AUTOSAR XML (schema 3.1.2)
package /Components/SWC_TrbActSys
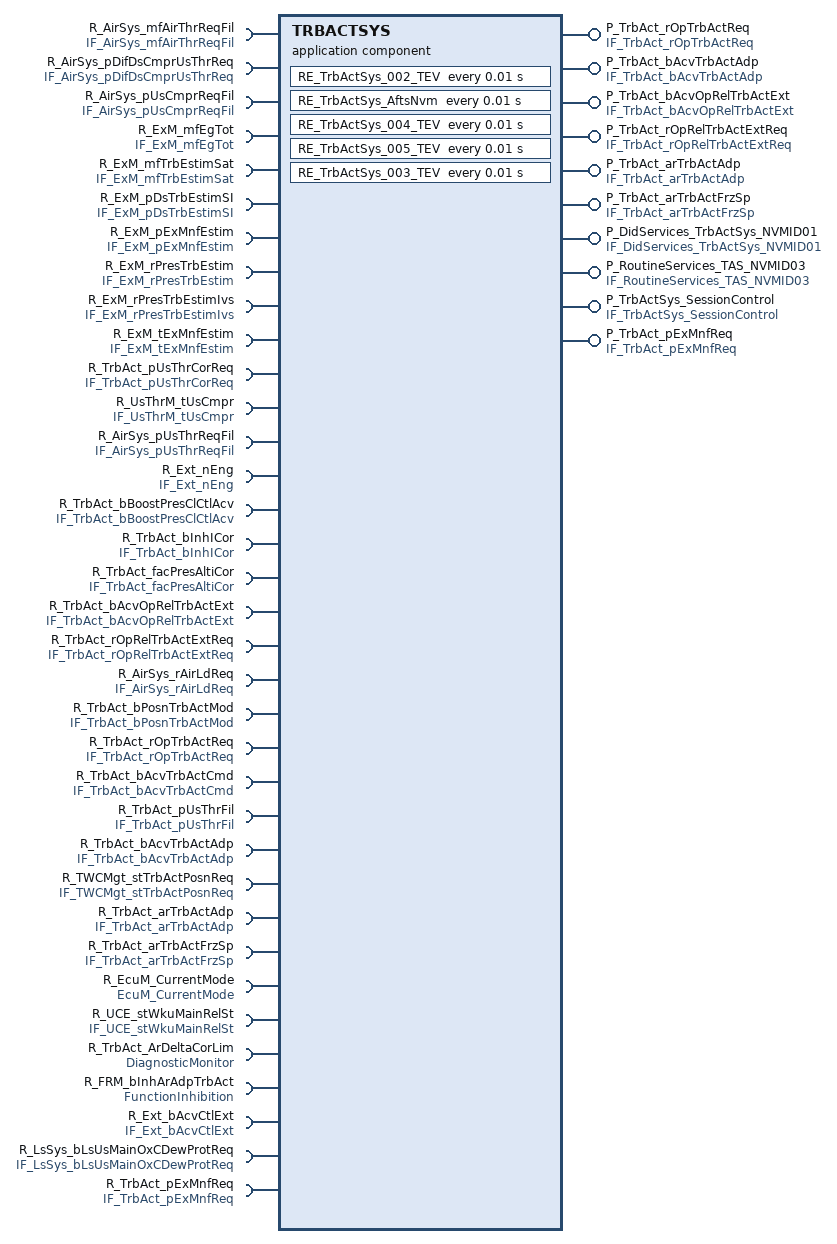
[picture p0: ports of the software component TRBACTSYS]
  application software component type TRBACTSYS
    32 x require port:
      R_AirSys_mfAirThrReqFil: unqueued-receiver-com-spec{data-element=AirSys_mfAirThrReqFil, init-value=ConstantValue, resync-time=0}, required-interface=IF_AirSys_mfAirThrReqFil  # Receiver of interface IF_AirSys_mfAirThrReqFil - Requirement Reference: [01552_10_02517-TrbActSys-I004(0)]
      R_AirSys_pDifDsCmprUsThrReq: unqueued-receiver-com-spec{data-element=AirSys_pDifDsCmprUsThrReq, init-value=ConstantValue1, resync-time=0}, required-interface=IF_AirSys_pDifDsCmprUsThrReq  # Receiver of interface IF_AirSys_pDifDsCmprUsThrReq - Requirement Reference: [01552_10_02517-TrbActSys-I005(1)]
      R_AirSys_pUsCmprReqFil: unqueued-receiver-com-spec{data-element=AirSys_pUsCmprReqFil, init-value=ConstantValue3, resync-time=0}, required-interface=IF_AirSys_pUsCmprReqFil  # Receiver of interface IF_AirSys_pUsCmprReqFil - Requirement Reference: [01552_10_02517-TrbActSys-I006(0)]
      R_ExM_mfEgTot: unqueued-receiver-com-spec{data-element=ExM_mfEgTot, init-value=ExM_mfEgTot_Cst, resync-time=0}, required-interface=IF_ExM_mfEgTot  # Receiver of interface IF_ExM_mfEgTot - Requirement Reference: [01552_10_02517-TrbActSys-I007(0)]
      R_ExM_mfTrbEstimSat: unqueued-receiver-com-spec{data-element=ExM_mfTrbEstimSat, init-value=ExM_mfTrbEstimSat_Cst, resync-time=0}, required-interface=IF_ExM_mfTrbEstimSat  # Receiver of interface IF_ExM_mfTrbEstimSat - Requirement Reference: [01552_10_02517-TrbActSys-I008(0)]
      R_ExM_pDsTrbEstimSI: unqueued-receiver-com-spec{data-element=ExM_pDsTrbEstimSI, init-value=ConstantValue5, resync-time=0}, required-interface=IF_ExM_pDsTrbEstimSI  # Receiver of interface IF_ExM_pDsTrbEstimSI - Requirement Reference: [01552_10_02517-TrbActSys-I009(0)]
      R_ExM_pExMnfEstim: unqueued-receiver-com-spec{data-element=ExM_pExMnfEstim, init-value=ConstantValue7, resync-time=0}, required-interface=IF_ExM_pExMnfEstim  # Receiver of interface IF_ExM_pExMnfEstim - Requirement Reference: [01552_10_02517-TrbActSys-I010(0)]
      R_ExM_rPresTrbEstim: unqueued-receiver-com-spec{data-element=ExM_rPresTrbEstim, init-value=ExM_rPresTrbEstim_Cst, resync-time=0}, required-interface=IF_ExM_rPresTrbEstim  # Receiver of interface IF_ExM_rPresTrbEstim - Requirement Reference: [01552_10_02517-TrbActSys-I011(0)]
      R_ExM_rPresTrbEstimIvs: unqueued-receiver-com-spec{data-element=ExM_rPresTrbEstimIvs, init-value=ExM_rPresTrbEstimIvs_Cst, resync-time=0}, required-interface=IF_ExM_rPresTrbEstimIvs  # Receiver of interface IF_ExM_rPresTrbEstimIvs - Requirement Reference: [01552_10_02517-TrbActSys-I012(1)]
      R_ExM_tExMnfEstim: unqueued-receiver-com-spec{data-element=ExM_tExMnfEstim, init-value=ExM_tExMnfEstim_Cst, resync-time=0}, required-interface=IF_ExM_tExMnfEstim  # Receiver of interface IF_ExM_tExMnfEstim - Requirement Reference: [01552_10_02517-TrbActSys-I013(0)]
      R_TrbAct_pUsThrCorReq: unqueued-receiver-com-spec{data-element=TrbAct_pUsThrCorReq, init-value=ConstantValue9, resync-time=0}, required-interface=IF_TrbAct_pUsThrCorReq  # Receiver of interface IF_TrbAct_pUsThrCorReq - Requirement Reference: [01552_10_02517-TrbActSys-I014(0)]
      R_UsThrM_tUsCmpr: unqueued-receiver-com-spec{data-element=UsThrM_tUsCmpr, init-value=ConstantValue11, resync-time=0}, required-interface=IF_UsThrM_tUsCmpr  # Receiver of interface IF_UsThrM_tUsCmpr - Requirement Reference: [01552_10_02517-TrbActSys-I016(1)]
      R_AirSys_pUsThrReqFil: unqueued-receiver-com-spec{data-element=AirSys_pUsThrReqFil, init-value=ConstantValue13, resync-time=0}, required-interface=IF_AirSys_pUsThrReqFil  # Receiver of interface IF_AirSys_pUsThrReqFil - Requirement Reference: [01552_10_02517-TrbActSys-I020(0)]
      R_Ext_nEng: unqueued-receiver-com-spec{data-element=Ext_nEng, init-value=ConstantValue15, resync-time=0}, required-interface=IF_Ext_nEng  # Receiver of interface IF_Ext_nEng - Requirement Reference: [01552_10_02517-TrbActSys-I021(0)]
      R_TrbAct_bBoostPresClCtlAcv: unqueued-receiver-com-spec{data-element=TrbAct_bBoostPresClCtlAcv, init-value=ConstantValue17, resync-time=0}, required-interface=IF_TrbAct_bBoostPresClCtlAcv  # Receiver of interface IF_TrbAct_bBoostPresClCtlAcv - Requirement Reference: [01552_10_02517-TrbActSys-I023(0)]
      R_TrbAct_bInhICor: unqueued-receiver-com-spec{data-element=TrbAct_bInhICor, init-value=ConstantValue19, resync-time=0}, required-interface=IF_TrbAct_bInhICor  # Receiver of interface IF_TrbAct_bInhICor - Requirement Reference: [01552_10_02517-TrbActSys-I024(0)]
      R_TrbAct_facPresAltiCor: unqueued-receiver-com-spec{data-element=TrbAct_facPresAltiCor, init-value=ConstantValue21, resync-time=0}, required-interface=IF_TrbAct_facPresAltiCor  # Receiver of interface IF_TrbAct_facPresAltiCor - Requirement Reference: [01552_10_02517-TrbActSys-I028(1)]
      R_TrbAct_bAcvOpRelTrbActExt: unqueued-receiver-com-spec{data-element=TrbAct_bAcvOpRelTrbActExt, init-value=TrbAct_bAcvOpRelTrbActExt_Cst, resync-time=0}, required-interface=IF_TrbAct_bAcvOpRelTrbActExt  # Receiver of interface IF_TrbAct_bAcvOpRelTrbActExt - Requirement Reference: [01552_10_02517-TrbActSys-I032(0)]
      R_TrbAct_rOpRelTrbActExtReq: unqueued-receiver-com-spec{data-element=TrbAct_rOpRelTrbActExtReq, init-value=TrbAct_rOpRelTrbActExtReq_Cst, resync-time=0}, required-interface=IF_TrbAct_rOpRelTrbActExtReq  # Receiver of interface IF_TrbAct_rOpRelTrbActExtReq - Requirement Reference: [01552_10_02517-TrbActSys-I033(0)]
      R_AirSys_rAirLdReq: unqueued-receiver-com-spec{data-element=AirSys_rAirLdReq, init-value=AirSys_rAirLdReq_Cst, resync-time=0}, required-interface=IF_AirSys_rAirLdReq  # Receiver of interface IF_AirSys_rAirLdReq - Requirement Reference: [01552_10_02517-TrbActSys-I034(0)]
      R_TrbAct_bPosnTrbActMod: unqueued-receiver-com-spec{data-element=TrbAct_bPosnTrbActMod, init-value=ConstantValue23, resync-time=0}, required-interface=IF_TrbAct_bPosnTrbActMod  # Receiver of interface IF_TrbAct_bPosnTrbActMod - Requirement Reference: [01552_10_02517-TrbActSys-I038(0)]
      R_TrbAct_rOpTrbActReq: unqueued-receiver-com-spec{data-element=TrbAct_rOpTrbActReq, init-value=ConstantValue25, resync-time=0}, required-interface=IF_TrbAct_rOpTrbActReq  # Receiver of interface IF_TrbAct_rOpTrbActReq - Requirement Reference: [01552_10_02517-TrbActSys-I050(0)]
      R_TrbAct_bAcvTrbActCmd: unqueued-receiver-com-spec{data-element=TrbAct_bAcvTrbActCmd, init-value=ConstantValue27, resync-time=0}, required-interface=IF_TrbAct_bAcvTrbActCmd  # Receiver of interface IF_TrbAct_bAcvTrbActCmd - Requirement Reference: [01552_10_02517-TrbActSys-I051(0)]
      R_TrbAct_pUsThrFil: unqueued-receiver-com-spec{data-element=TrbAct_pUsThrFil, init-value=ConstantValue29, resync-time=0}, required-interface=IF_TrbAct_pUsThrFil  # Receiver of interface IF_TrbAct_pUsThrFil - Requirement Reference: [01552_10_02517-TrbActSys-I053(0)]
      R_TrbAct_bAcvTrbActAdp: unqueued-receiver-com-spec{data-element=TrbAct_bAcvTrbActAdp, init-value=ConstantValue31, resync-time=0}, required-interface=IF_TrbAct_bAcvTrbActAdp  # Receiver of interface IF_TrbAct_bAcvTrbActAdp - Requirement Reference: [01552_10_02517-TrbActSys-I056(0)]
      R_TWCMgt_stTrbActPosnReq: unqueued-receiver-com-spec{data-element=TWCMgt_stTrbActPosnReq, init-value=TWCMgt_stTrbActPosnReq_Cst, resync-time=0}, required-interface=IF_TWCMgt_stTrbActPosnReq  # Receiver of interface IF_TWCMgt_stTrbActPosnReq - Requirement Reference: [01552_10_02517-TrbActSys-I060(0)]
      R_TrbAct_arTrbActAdp: unqueued-receiver-com-spec{data-element=TrbAct_arTrbActAdp, init-value=TrbAct_arTrbActAdp_Cst, resync-time=0}, required-interface=IF_TrbAct_arTrbActAdp  # Receiver of interface IF_TrbAct_arTrbActAdp - Requirement Reference: [01552_10_02517-TrbActSys-I066(0)]
      R_TrbAct_arTrbActFrzSp: unqueued-receiver-com-spec{data-element=TrbAct_arTrbActFrzSp, init-value=TrbAct_arTrbActFrzSp_Cst, resync-time=0}, required-interface=IF_TrbAct_arTrbActFrzSp  # Receiver of interface IF_TrbAct_arTrbActFrzSp - Requirement Reference: [01552_10_02517-TrbActSys-I067(0)]
      R_EcuM_CurrentMode: required-interface=EcuM_CurrentMode
      R_UCE_stWkuMainRelSt: required-interface=IF_UCE_stWkuMainRelSt
      R_TrbAct_ArDeltaCorLim: required-interface=DiagnosticMonitor  # 01552_10_02517-TrbActSys-I044(0)
      R_FRM_bInhArAdpTrbAct: required-interface=FunctionInhibition  # 01552_10_02517-TrbActSys-I045(0)
    9 x provide port:
      P_TrbAct_rOpTrbActReq: unqueued-sender-com-spec{data-element=TrbAct_rOpTrbActReq, can-invalidate=false, init-value=ConstantValue33}, provided-interface=IF_TrbAct_rOpTrbActReq
      P_TrbAct_bAcvTrbActAdp: unqueued-sender-com-spec{data-element=TrbAct_bAcvTrbActAdp, can-invalidate=false, init-value=ConstantValue35}, provided-interface=IF_TrbAct_bAcvTrbActAdp
      P_TrbAct_bAcvOpRelTrbActExt: unqueued-sender-com-spec{data-element=TrbAct_bAcvOpRelTrbActExt, can-invalidate=false, init-value=TrbAct_bAcvOpRelTrbActExt_Cst}, provided-interface=IF_TrbAct_bAcvOpRelTrbActExt
      P_TrbAct_rOpRelTrbActExtReq: unqueued-sender-com-spec{data-element=TrbAct_rOpRelTrbActExtReq, can-invalidate=false, init-value=TrbAct_rOpRelTrbActExtReq_Cst}, provided-interface=IF_TrbAct_rOpRelTrbActExtReq
      P_TrbAct_arTrbActAdp: unqueued-sender-com-spec{data-element=TrbAct_arTrbActAdp, can-invalidate=false, init-value=TrbAct_arTrbActAdp_Cst}, provided-interface=IF_TrbAct_arTrbActAdp
      P_TrbAct_arTrbActFrzSp: unqueued-sender-com-spec{data-element=TrbAct_arTrbActFrzSp, can-invalidate=false, init-value=TrbAct_arTrbActFrzSp_Cst}, provided-interface=IF_TrbAct_arTrbActFrzSp
      P_DidServices_TrbActSys_NVMID01: provided-interface=IF_DidServices_TrbActSys_NVMID01
        provided-com-specs:
          operation=WriteData, queue-length=1
          operation=ConditionCheckWrite, queue-length=1
          operation=ConditionCheckRead, queue-length=1
          operation=ReadDataLength, queue-length=1
          operation=ReadData, queue-length=1
      P_RoutineServices_TAS_NVMID03: provided-com-specs=[{operation=Start, queue-length=1}, {operation=RequestResults, queue-length=1}], provided-interface=IF_RoutineServices_TAS_NVMID03
      P_TrbActSys_SessionControl: provided-com-specs=[{operation=GetSesChgPermission, queue-length=1}, {operation=ChangeIndication, queue-length=1}], provided-interface=IF_TrbActSys_SessionControl
    require port R_Ext_bAcvCtlExt: unqueued-receiver-com-spec{data-element=Ext_bAcvCtlExt, init-value=Ext_bAcvCtlExt_Cst, resync-time=0}, required-interface=IF_Ext_bAcvCtlExt
    require port R_LsSys_bLsUsMainOxCDewProtReq: unqueued-receiver-com-spec{data-element=LsSys_bLsUsMainOxCDewProtReq, init-value=LsSys_bLsUsMainOxCDewProtReq_Cst, resync-time=0}, required-interface=IF_LsSys_bLsUsMainOxCDewProtReq
    provide port P_TrbAct_pExMnfReq: unqueued-sender-com-spec{data-element=TrbAct_pExMnfReq, can-invalidate=false, init-value=ConstantValue37}, provided-interface=IF_TrbAct_pExMnfReq
    require port R_TrbAct_pExMnfReq: unqueued-receiver-com-spec{data-element=TrbAct_pExMnfReq, init-value=ConstantValue39, resync-time=0}, required-interface=IF_TrbAct_pExMnfReq
  47 x constant specification:
    AirSys_rAirLdReq_Cst
      value:
        integer literal AirSys_rAirLdReq_Cst: type=DT_AirSys_rAirLdReq, value=0
    ConstantValue
      value:
        integer literal ConstantValue: type=DT_AirSys_mfAirThrReqFil, value=0
    ConstantValue1
      value:
        integer literal ConstantValue1: type=DT_AirSys_pDifDsCmprUsThrReq, value=0
    ConstantValue11
      value:
        integer literal ConstantValue11: type=DT_UsThrM_tUsCmpr, value=0
    ConstantValue13
      value:
        integer literal ConstantValue13: type=DT_AirSys_pUsThrReqFil, value=0
    ConstantValue15
      value:
        integer literal ConstantValue15: type=DT_Ext_nEng, value=0
    ConstantValue17
      value:
        boolean literal ConstantValue17: type=DT_TrbAct_bBoostPresClCtlAcv, value=false
    ConstantValue19
      value:
        boolean literal ConstantValue19: type=DT_TrbAct_bInhICor, value=false
    ConstantValue21
      value:
        integer literal ConstantValue21: type=DT_TrbAct_facPresAltiCor, value=0
    ConstantValue23
      value:
        boolean literal ConstantValue23: type=DT_TrbAct_bPosnTrbActMod, value=false
    ConstantValue25
      value:
        integer literal ConstantValue25: type=DT_TrbAct_rOpTrbActReq, value=0
    ConstantValue27
      value:
        boolean literal ConstantValue27: type=DT_TrbAct_bAcvTrbActCmd, value=false
    ConstantValue29
      value:
        integer literal ConstantValue29: type=DT_TrbAct_pUsThrFil, value=0
    ConstantValue3
      value:
        integer literal ConstantValue3: type=DT_AirSys_pUsCmprReqFil, value=0
    ConstantValue31
      value:
        boolean literal ConstantValue31: type=DT_TrbAct_bAcvTrbActAdp, value=false
    ConstantValue33
      value:
        integer literal ConstantValue33: type=DT_TrbAct_rOpTrbActReq, value=0
    ConstantValue35
      value:
        boolean literal ConstantValue35: type=DT_TrbAct_bAcvTrbActAdp, value=false
    ConstantValue37
      value:
        integer literal ConstantValue37: type=DT_TrbAct_pExMnfReq, value=0
    ConstantValue39
      value:
        integer literal ConstantValue39: type=DT_TrbAct_pExMnfReq, value=0
    ConstantValue5
      value:
        integer literal ConstantValue5: type=DT_ExM_pDsTrbEstimSI, value=0
    ConstantValue7
      value:
        integer literal ConstantValue7: type=DT_ExM_pExMnfEstim, value=0
    ConstantValue9
      value:
        integer literal ConstantValue9: type=DT_TrbAct_pUsThrCorReq, value=0
    ExM_mfEgTot_Cst
      value:
        integer literal ExM_mfEgTot_Cst: type=DT_ExM_mfEgTot, value=0
    ExM_mfTrbEstimSat_Cst
      value:
        integer literal ExM_mfTrbEstimSat_Cst: type=DT_ExM_mfTrbEstimSat, value=0
    ExM_rPresTrbEstim_Cst
      value:
        integer literal ExM_rPresTrbEstim_Cst: type=DT_ExM_rPresTrbEstim, value=0
    ExM_rPresTrbEstimIvs_Cst
      value:
        integer literal ExM_rPresTrbEstimIvs_Cst: type=DT_ExM_rPresTrbEstimIvs, value=0
    ExM_tExMnfEstim_Cst
      value:
        integer literal ExM_tExMnfEstim_Cst: type=DT_ExM_tExMnfEstim, value=4800
    Ext_bAcvCtlExt_Cst
      value:
        boolean literal Ext_bAcvCtlExt_Cst: type=DT_Ext_bAcvCtlExt, value=false
    LsSys_bLsUsMainOxCDewProtReq_Cst
      value:
        boolean literal LsSys_bLsUsMainOxCDewProtReq_Cst: type=DT_LsSys_bLsUsMainOxCDewProtReq, value=false
    TA_facAdpArTrbActErrFil_irv_Cst
      value:
        integer literal TA_facAdpArTrbActErrFil_irv_Cst: type=DT_TrbAct_facAdpArTrbActErrFil_irv, value=-65535
    TA_rOpTrbActAirExtModReq_irv_Cst
      value:
        integer literal TA_rOpTrbActAirExtModReq_irv_Cst: type=DT_TrbAct_rOpTrbActAirExtModReq_irv, value=0
    TAS_pGradUsThrMesCorFil_irv_Cst
      value:
        integer literal TAS_pGradUsThrMesCorFil_irv_Cst: type=DT_TrbAct_pGradUsThrMesCorFil_irv, value=-32768
    TrbAct_arTrbActAdp_Cst
      value:
        integer literal TrbAct_arTrbActAdp_Cst: type=DT_TrbAct_arTrbActAdp, value=0
    TrbAct_arTrbActFrzSp_Cst
      value:
        integer literal TrbAct_arTrbActFrzSp_Cst: type=DT_TrbAct_arTrbActFrzSp, value=0
    TrbAct_arTrbActReq_irv_Cst
      value:
        integer literal TrbAct_arTrbActReq_irv_Cst: type=DT_TrbAct_arTrbActReq_irv, value=0
    TrbAct_bAcvOpRelTrbActExt_Cst
      value:
        boolean literal TrbAct_bAcvOpRelTrbActExt_Cst: type=DT_TrbAct_bAcvOpRelTrbActExt, value=true
    TrbAct_effCmpr_irv_Cst
      value:
        integer literal TrbAct_effCmpr_irv_Cst: type=DT_TrbAct_effCmpr_irv, value=0
    TrbAct_effTrb_irv_Cst
      value:
        integer literal TrbAct_effTrb_irv_Cst: type=DT_TrbAct_effTrb_irv, value=0
    TrbAct_facAdpArTrbActErr_irv_Cst
      value:
        integer literal TrbAct_facAdpArTrbActErr_irv_Cst: type=DT_TrbAct_facAdpArTrbActErr_irv, value=-65535
    TrbAct_pGradUsThrReqFil_irv_Cst
      value:
        integer literal TrbAct_pGradUsThrReqFil_irv_Cst: type=DT_TrbAct_pGradUsThrReqFil_irv, value=-32768
    TrbAct_rOpRelTrbActExtReq_Cst
      value:
        integer literal TrbAct_rOpRelTrbActExtReq_Cst: type=DT_TrbAct_rOpRelTrbActExtReq, value=0
    TrbActSys_ctLockRqAftsNvm_Cst
      value:
        integer literal TrbActSys_ctLockRqAftsNvm_Cst: type=DT_TrbActSys_ctLockRqAftsNvm, value=0
    TrbActSys_IDAftsNvm_Cst
      value:
        integer literal TrbActSys_IDAftsNvm_Cst: type=DT_TrbActSys_IDAftsNvm, value=0
    TrbActSys_LockedAftsNvm_Cst
      value:
        boolean literal TrbActSys_LockedAftsNvm_Cst: type=DT_TrbActSys_LockedAftsNvm, value=false
    TrbActSys_stAftsNvm_Cst
      value:
        integer literal TrbActSys_stAftsNvm_Cst: type=DT_TrbActSys_stAftsNvm, value=0
    TrbActSys_stRstNvmRtn_Cst
      value:
        integer literal TrbActSys_stRstNvmRtn_Cst: type=DT_TrbActSys_stRstNvmRtn, value=0
    TWCMgt_stTrbActPosnReq_Cst
      value:
        integer literal TWCMgt_stTrbActPosnReq_Cst: type=DT_TWCMgt_stTrbActPosnReq, value=0
  internal behavior IB_TrbActSys: component=TRBACTSYS
    operation invoked event EV_TAS_AftsNvmWrite_NVMID01: start-on-event=RE_TrbActSys_AftsNvmWrite, operation=P_DidServices_TrbActSys_NVMID01.WriteData
    operation invoked event EV_TAS_AftsGetSesChgPerm: start-on-event=RE_TrbActSys_AftsGetSesChgPerm, operation=P_TrbActSys_SessionControl.GetSesChgPermission
    timing event EV_TrbActSys_002_TEV: start-on-event=RE_TrbActSys_002_TEV, period=0.01
    timing event EV_TrbActSys_AftsNvm: start-on-event=RE_TrbActSys_AftsNvm, period=0.01
    mode switch event EV_TrbActSys_AftrsInit: start-on-event=RE_TrbActSys_AftrsInit, activation=ENTRY, mode=R_EcuM_CurrentMode.currentMode.RUN
    mode switch event EV_TrbActSys_001_MSE: start-on-event=RE_TrbActSys_001_MSE, activation=ENTRY, mode=R_EcuM_CurrentMode.currentMode.RUN
    timing event EV_TrbActSys_004_TEV: start-on-event=RE_TrbActSys_004_TEV, period=0.01
    6 x operation invoked event:
      EV_TAS_RstRqResults_NVMID03: start-on-event=RE_TrbActSys_RstRqResults, operation=P_RoutineServices_TAS_NVMID03.RequestResults
      EV_TAS_AftsNvmChkWrite_NVMID01: start-on-event=RE_TrbActSys_AftsNvmChkWrite, operation=P_DidServices_TrbActSys_NVMID01.ConditionCheckWrite
      EV_TAS_AftsSesChgInd: start-on-event=RE_TrbActSys_AftsSesChgInd, operation=P_TrbActSys_SessionControl.ChangeIndication
      EV_TAS_RstStart_NVMID03: start-on-event=RE_TrbActSys_RstStart, operation=P_RoutineServices_TAS_NVMID03.Start
      EV_TAS_AftsNvmChkRead_NVMID01: start-on-event=RE_TrbActSys_AftsNvmChkRead, operation=P_DidServices_TrbActSys_NVMID01.ConditionCheckRead
      EV_TAS_AftsNvmRead_NVMID01: start-on-event=RE_TrbActSys_AftsNvmRead, operation=P_DidServices_TrbActSys_NVMID01.ReadData
    timing event EV_TrbActSys_005_TEV: start-on-event=RE_TrbActSys_005_TEV, period=0.01
    operation invoked event EV_TAS_AftsNvmRDL_NVMID01: start-on-event=RE_TrbActSys_AftsNvmRDL, operation=P_DidServices_TrbActSys_NVMID01.ReadDataLength
    timing event EV_TrbActSys_003_TEV: start-on-event=RE_TrbActSys_003_TEV, period=0.01
    13 x inter runnable variable, all with sw-calibration-access=READ-WRITE, communication-approach=EXPLICIT:
      TrbAct_pGradUsThrReqFil_irv: type=DT_TrbAct_pGradUsThrReqFil_irv, init-value=TrbAct_pGradUsThrReqFil_irv_Cst  # [01552_10_02517-TrbActSys-I061(2)] - Gradient de consigne de pression de suralimentation filtré. Dim 1x1
      TrbAct_pGradUsThrMesCorFil_irv: type=DT_TrbAct_pGradUsThrMesCorFil_irv, init-value=TAS_pGradUsThrMesCorFil_irv_Cst  # [01552_10_02517-TrbActSys-I062(2)] - Gradient de mesure de pression de suralimentation filtré. Dim 1x1
      TrbAct_effTrb_irv: type=DT_TrbAct_effTrb_irv, init-value=TrbAct_effTrb_irv_Cst  # [01552_10_02517-TrbActSys-I003(2)] - Efficacite de la turbine Dim = 1x1
      TrbActSys_stAftsNvm: type=DT_TrbActSys_stAftsNvm, init-value=TrbActSys_stAftsNvm_Cst  # [01552_10_02517-TrbActSys-I071(0)] - Manage the type of aftersale service called
      TrbActSys_stRstNvmRtn: type=DT_TrbActSys_stRstNvmRtn, init-value=TrbActSys_stRstNvmRtn_Cst  # [01552_10_02517-TrbActSys-I075(0)] - status of the corresponding routine service
      TrbActSys_ctLockRqAftsNvm: type=DT_TrbActSys_ctLockRqAftsNvm, init-value=TrbActSys_ctLockRqAftsNvm_Cst  # [01552_10_02517-TrbActSys-I072(0)] - guarantee the consistency of the data and support RDBI request to read several DIDs
      TrbAct_arTrbActReq_irv: type=DT_TrbAct_arTrbActReq_irv, init-value=TrbAct_arTrbActReq_irv_Cst  # [01552_10_02517-TrbActSys-I001(2)] - Consigne de section efficace de la wastegate Dim = 1x1
      TrbActSys_LockedAftsNvm: type=DT_TrbActSys_LockedAftsNvm, init-value=TrbActSys_LockedAftsNvm_Cst  # [01552_10_02517-TrbActSys-I073(0)] - the consistency of the data is guarantee
      TrbAct_effCmpr_irv: type=DT_TrbAct_effCmpr_irv, init-value=TrbAct_effCmpr_irv_Cst  # [01552_10_02517-TrbActSys-I002(2)] - Efficacite du compresseur Dim = 1x1
      TrbAct_facAdpArTrbActErrFil_irv: type=DT_TrbAct_facAdpArTrbActErrFil_irv, init-value=TA_facAdpArTrbActErrFil_irv_Cst  # [01552_10_02517-TrbActSys-I064(1)] - Erreur relative de section wastegate pour l'adaptation, filtrée. Dim = 1x1
      TrbAct_rOpTrbActAirExtModReq_irv: type=DT_TrbAct_rOpTrbActAirExtModReq_irv, init-value=TA_rOpTrbActAirExtModReq_irv_Cst  # [01552_10_02517-TrbActSys-I046(2)] - Valeur de la consigne de position de la wastegate en mode cartographie Dim = 1x1
      TrbActSys_IDAftsNvm: type=DT_TrbActSys_IDAftsNvm, init-value=TrbActSys_IDAftsNvm_Cst  # [01552_10_02517-TrbActSys-I074(0)] - manage which NVMID to handle
      TrbAct_facAdpArTrbActErr_irv: type=DT_TrbAct_facAdpArTrbActErr_irv, init-value=TrbAct_facAdpArTrbActErr_irv_Cst  # [01552_10_02517-TrbActSys-I049(2)] - Erreur relative de section wastegate pour l'adaptation Dim = 1x1
    port-api-option enable-take-address=false, indirect-api=false, port=P_DidServices_TrbActSys_NVMID01:
      port-arg-values:
        integer literal PAV_TrbActSys_NVMID01: type=UInt8, value=1
    port-api-option enable-take-address=false, indirect-api=false, port=P_RoutineServices_TAS_NVMID03:
      port-arg-values:
        integer literal PAV_TrbActSys_NVMID03: type=UInt8, value=3
    16 x runnable:
      RE_TrbActSys_005_TEV  # 01552_10_02517-TrbActSys-A005(1)
        6 x data receive point:
          dr_TrbAct_facPresAltiCor: data-element=R_TrbAct_facPresAltiCor.TrbAct_facPresAltiCor
          dr_TrbAct_rOpRelTrbActExtReq: data-element=R_TrbAct_rOpRelTrbActExtReq.TrbAct_rOpRelTrbActExtReq
          dr_AirSys_rAirLdReq: data-element=R_AirSys_rAirLdReq.AirSys_rAirLdReq
          dr_TWCMgt_stTrbActPosnReq: data-element=R_TWCMgt_stTrbActPosnReq.TWCMgt_stTrbActPosnReq
          dr_LsSys_bLsUsMainOxCDewProtReq: data-element=R_LsSys_bLsUsMainOxCDewProtReq.LsSys_bLsUsMainOxCDewProtReq
          dr_Ext_nEng: data-element=R_Ext_nEng.Ext_nEng
        data send point ds_TrbAct_bAcvOpRelTrbActExt: data-element=P_TrbAct_bAcvOpRelTrbActExt.TrbAct_bAcvOpRelTrbActExt
        data send point ds_TrbAct_rOpRelTrbActExtReq: data-element=P_TrbAct_rOpRelTrbActExtReq.TrbAct_rOpRelTrbActExtReq
      RE_TrbActSys_AftsNvm: read-variable=[TrbActSys_ctLockRqAftsNvm, TrbActSys_IDAftsNvm, TrbActSys_LockedAftsNvm, TrbActSys_stAftsNvm], written-variable=[TrbActSys_ctLockRqAftsNvm, TrbActSys_LockedAftsNvm, TrbActSys_stAftsNvm]  # 01552_10_02517-TrbActSys-A015(0)
        data receive point dr_Ext_nEng: data-element=R_Ext_nEng.Ext_nEng
      RE_TrbActSys_RstRqResults: read-variable=[TrbActSys_stAftsNvm, TrbActSys_stRstNvmRtn, TrbActSys_IDAftsNvm], written-variable=TrbActSys_stAftsNvm  # 01552_10_02517-TrbActSys-A012(0)
      RE_TrbActSys_AftsNvmChkWrite: read-variable=[TrbActSys_stRstNvmRtn, TrbActSys_ctLockRqAftsNvm, TrbActSys_stAftsNvm, TrbActSys_IDAftsNvm, TrbActSys_LockedAftsNvm], written-variable=[TrbActSys_ctLockRqAftsNvm, TrbActSys_stAftsNvm, TrbActSys_IDAftsNvm, TrbActSys_LockedAftsNvm]  # 01552_10_02517-TrbActSys-A008(0)
        data receive point dr_Ext_nEng: data-element=R_Ext_nEng.Ext_nEng
      RE_TrbActSys_AftsNvmChkRead: read-variable=[TrbActSys_IDAftsNvm, TrbActSys_LockedAftsNvm, TrbActSys_stRstNvmRtn, TrbActSys_ctLockRqAftsNvm, TrbActSys_stAftsNvm], written-variable=[TrbActSys_IDAftsNvm, TrbActSys_LockedAftsNvm, TrbActSys_ctLockRqAftsNvm, TrbActSys_stAftsNvm]  # 01552_10_02517-TrbActSys-A006(0)
        data receive point dr_Ext_nEng: data-element=R_Ext_nEng.Ext_nEng
      RE_TrbActSys_AftsNvmRDL  # 01552_10_02517-TrbActSys-A010(0)
      RE_TrbActSys_001_MSE: written-variable=[TrbAct_facAdpArTrbActErrFil_irv, TrbAct_facAdpArTrbActErr_irv, TrbAct_effCmpr_irv, TrbAct_pGradUsThrMesCorFil_irv, TrbAct_pGradUsThrReqFil_irv, TrbAct_effTrb_irv, TrbAct_arTrbActReq_irv, TrbAct_rOpTrbActAirExtModReq_irv]  # 01552_10_02517-TrbActSys-A001(3)
        7 x data send point:
          ds_TrbAct_rOpRelTrbActExtReq: data-element=P_TrbAct_rOpRelTrbActExtReq.TrbAct_rOpRelTrbActExtReq
          ds_TrbAct_arTrbActFrzSp: data-element=P_TrbAct_arTrbActFrzSp.TrbAct_arTrbActFrzSp
          ds_TrbAct_pExMnfReq: data-element=P_TrbAct_pExMnfReq.TrbAct_pExMnfReq
          ds_TrbAct_rOpTrbActReq: data-element=P_TrbAct_rOpTrbActReq.TrbAct_rOpTrbActReq
          ds_TrbAct_bAcvOpRelTrbActExt: data-element=P_TrbAct_bAcvOpRelTrbActExt.TrbAct_bAcvOpRelTrbActExt
          ds_TrbAct_arTrbActAdp: data-element=P_TrbAct_arTrbActAdp.TrbAct_arTrbActAdp
          ds_TrbAct_bAcvTrbActAdp: data-element=P_TrbAct_bAcvTrbActAdp.TrbAct_bAcvTrbActAdp
        sync call SC_TrbAct_ArDeltaCorLim: operation=R_TrbAct_ArDeltaCorLim.SetEventStatus
      RE_TrbActSys_003_TEV: read-variable=[TrbAct_facAdpArTrbActErr_irv, TrbAct_arTrbActReq_irv, TrbAct_pGradUsThrReqFil_irv, TrbAct_effTrb_irv, TrbAct_effCmpr_irv, TrbAct_pGradUsThrMesCorFil_irv, TrbAct_facAdpArTrbActErrFil_irv], written-variable=[TrbAct_facAdpArTrbActErr_irv, TrbAct_pGradUsThrReqFil_irv, TrbAct_pGradUsThrMesCorFil_irv, TrbAct_facAdpArTrbActErrFil_irv]  # 01552_10_02517-TrbActSys-A003(4)
        17 x data receive point:
          dr_ExM_mfEgTot: data-element=R_ExM_mfEgTot.ExM_mfEgTot
          dr_AirSys_pUsThrReqFil: data-element=R_AirSys_pUsThrReqFil.AirSys_pUsThrReqFil
          dr_TrbAct_bBoostPresClCtlAcv: data-element=R_TrbAct_bBoostPresClCtlAcv.TrbAct_bBoostPresClCtlAcv
          dr_TrbAct_pUsThrCorReq: data-element=R_TrbAct_pUsThrCorReq.TrbAct_pUsThrCorReq
          dr_TrbAct_arTrbActAdp: data-element=R_TrbAct_arTrbActAdp.TrbAct_arTrbActAdp
          dr_TrbAct_bInhICor: data-element=R_TrbAct_bInhICor.TrbAct_bInhICor
          dr_AirSys_mfAirThrReqFil: data-element=R_AirSys_mfAirThrReqFil.AirSys_mfAirThrReqFil
          dr_ExM_tExMnfEstim: data-element=R_ExM_tExMnfEstim.ExM_tExMnfEstim
          dr_TrbAct_facPresAltiCor: data-element=R_TrbAct_facPresAltiCor.TrbAct_facPresAltiCor
          dr_ExM_pExMnfEstim: data-element=R_ExM_pExMnfEstim.ExM_pExMnfEstim
          dr_ExM_rPresTrbEstimIvs: data-element=R_ExM_rPresTrbEstimIvs.ExM_rPresTrbEstimIvs
          dr_TrbAct_arTrbActFrzSp: data-element=R_TrbAct_arTrbActFrzSp.TrbAct_arTrbActFrzSp
          drp_Ext_bAcvCtlExt: data-element=R_Ext_bAcvCtlExt.Ext_bAcvCtlExt
          dr_Ext_nEng: data-element=R_Ext_nEng.Ext_nEng
          dr_TrbAct_pUsThrFil: data-element=R_TrbAct_pUsThrFil.TrbAct_pUsThrFil
          dr_UsThrM_tUsCmpr: data-element=R_UsThrM_tUsCmpr.UsThrM_tUsCmpr
          dr_AirSys_pUsCmprReqFil: data-element=R_AirSys_pUsCmprReqFil.AirSys_pUsCmprReqFil
        data send point ds_TrbAct_arTrbActFrzSp: data-element=P_TrbAct_arTrbActFrzSp.TrbAct_arTrbActFrzSp
        data send point ds_TrbAct_arTrbActAdp: data-element=P_TrbAct_arTrbActAdp.TrbAct_arTrbActAdp
        data send point ds_TrbAct_bAcvTrbActAdp: data-element=P_TrbAct_bAcvTrbActAdp.TrbAct_bAcvTrbActAdp
        sync call SC_TrbAct_ArDeltaCorLim: operation=R_TrbAct_ArDeltaCorLim.SetEventStatus
        sync call SC_FRM_bInhArAdpTrbAct: operation=R_FRM_bInhArAdpTrbAct.GetFunctionPermission
      RE_TrbActSys_AftsSesChgInd: read-variable=TrbActSys_stRstNvmRtn, written-variable=TrbActSys_IDAftsNvm  # 01552_10_02517-TrbActSys-A014(0)
      RE_TrbActSys_RstStart: read-variable=[TrbActSys_IDAftsNvm, TrbActSys_stRstNvmRtn, TrbActSys_ctLockRqAftsNvm, TrbActSys_stAftsNvm], written-variable=[TrbActSys_IDAftsNvm, TrbActSys_ctLockRqAftsNvm, TrbActSys_stAftsNvm]  # 01552_10_02517-TrbActSys-A011(0)
        data receive point dr_Ext_nEng: data-element=R_Ext_nEng.Ext_nEng
      RE_TrbActSys_AftsNvmRead: read-variable=[TrbActSys_LockedAftsNvm, TrbActSys_ctLockRqAftsNvm, TrbActSys_stAftsNvm], written-variable=[TrbActSys_LockedAftsNvm, TrbActSys_ctLockRqAftsNvm, TrbActSys_stAftsNvm]  # 01552_10_02517-TrbActSys-A007(0)
      RE_TrbActSys_004_TEV: read-variable=[TrbAct_facAdpArTrbActErrFil_irv, TrbAct_arTrbActReq_irv, TrbAct_rOpTrbActAirExtModReq_irv], written-variable=TrbAct_rOpTrbActAirExtModReq_irv  # 01552_10_02517-TrbActSys-A004(2)
        10 x data receive point:
          dr_TrbAct_rOpTrbActReq: data-element=R_TrbAct_rOpTrbActReq.TrbAct_rOpTrbActReq
          dr_TrbAct_bAcvOpRelTrbActExt: data-element=R_TrbAct_bAcvOpRelTrbActExt.TrbAct_bAcvOpRelTrbActExt
          dr_ExM_rPresTrbEstimIvs: data-element=R_ExM_rPresTrbEstimIvs.ExM_rPresTrbEstimIvs
          dr_TrbAct_bAcvTrbActCmd: data-element=R_TrbAct_bAcvTrbActCmd.TrbAct_bAcvTrbActCmd
          dr_TrbAct_bAcvTrbActAdp: data-element=R_TrbAct_bAcvTrbActAdp.TrbAct_bAcvTrbActAdp
          dr_Ext_nEng: data-element=R_Ext_nEng.Ext_nEng
          dr_TrbAct_facPresAltiCor: data-element=R_TrbAct_facPresAltiCor.TrbAct_facPresAltiCor
          dr_AirSys_rAirLdReq: data-element=R_AirSys_rAirLdReq.AirSys_rAirLdReq
          dr_TrbAct_bPosnTrbActMod: data-element=R_TrbAct_bPosnTrbActMod.TrbAct_bPosnTrbActMod
          dr_TrbAct_rOpRelTrbActExtReq: data-element=R_TrbAct_rOpRelTrbActExtReq.TrbAct_rOpRelTrbActExtReq
        data send point ds_TrbAct_rOpTrbActReq: data-element=P_TrbAct_rOpTrbActReq.TrbAct_rOpTrbActReq
      RE_TrbActSys_AftsNvmWrite: read-variable=TrbActSys_stAftsNvm, written-variable=TrbActSys_stAftsNvm  # 01552_10_02517-TrbActSys-A009(0)
      RE_TrbActSys_AftsGetSesChgPerm  # 01552_10_02517-TrbActSys-A013(0)
      RE_TrbActSys_AftrsInit: written-variable=[TrbActSys_ctLockRqAftsNvm, TrbActSys_LockedAftsNvm, TrbActSys_stAftsNvm, TrbActSys_stRstNvmRtn, TrbActSys_IDAftsNvm]  # 01552_10_02517-TrbActSys-A016(0)
      RE_TrbActSys_002_TEV: written-variable=[TrbAct_effTrb_irv, TrbAct_arTrbActReq_irv, TrbAct_effCmpr_irv]  # 01552_10_02517-TrbActSys-A002(0)
        14 x data receive point:
          dr_ExM_mfEgTot: data-element=R_ExM_mfEgTot.ExM_mfEgTot
          dr_AirSys_pDifDsCmprUsThrReq: data-element=R_AirSys_pDifDsCmprUsThrReq.AirSys_pDifDsCmprUsThrReq
          dr_UsThrM_tUsCmpr: data-element=R_UsThrM_tUsCmpr.UsThrM_tUsCmpr
          dr_ExM_pExMnfEstim: data-element=R_ExM_pExMnfEstim.ExM_pExMnfEstim
          dr_TrbAct_pUsThrCorReq: data-element=R_TrbAct_pUsThrCorReq.TrbAct_pUsThrCorReq
          dr_ExM_rPresTrbEstimIvs: data-element=R_ExM_rPresTrbEstimIvs.ExM_rPresTrbEstimIvs
          dr_AirSys_mfAirThrReqFil: data-element=R_AirSys_mfAirThrReqFil.AirSys_mfAirThrReqFil
          dr_ExM_rPresTrbEstim: data-element=R_ExM_rPresTrbEstim.ExM_rPresTrbEstim
          dr_ExM_tExMnfEstim: data-element=R_ExM_tExMnfEstim.ExM_tExMnfEstim
          dr_ExM_pDsTrbEstimSI: data-element=R_ExM_pDsTrbEstimSI.ExM_pDsTrbEstimSI
          dr_Ext_nEng: data-element=R_Ext_nEng.Ext_nEng
          dr_ExM_mfTrbEstimSat: data-element=R_ExM_mfTrbEstimSat.ExM_mfTrbEstimSat
          dr_TrbAct_pExMnfReq: data-element=R_TrbAct_pExMnfReq.TrbAct_pExMnfReq
          dr_AirSys_pUsCmprReqFil: data-element=R_AirSys_pUsCmprReqFil.AirSys_pUsCmprReqFil
  swc implementation Imp_TrbActSys: programming-language=C, behavior=IB_TrbActSys
    code-descriptors:
      code CodeDescriptor: type=SRC
        14 x xfile:
          TrbActSys_import_h: url=TrbActSys_import.h
          TrbActSys_nvm_h: url=TrbActSys_nvm.h
          TrbActSys_Version_h: url=TrbActSys_Version.h
          TrbActSys_h: url=TrbActSys.h
          TrbActSys_Version_c: url=TrbActSys_Version.c
          TrbActSys_Aftrs_c: url=TrbActSys_Aftrs.c
          TrbActSys_Aftrs_h: url=TrbActSys_Aftrs.h
          TrbActSys_c: url=TrbActSys.c
          TrbActSys_Def_c: url=TrbActSys_Def.c
          TrbActSys_private_h: url=TrbActSys_private.h
          TrbActSys_types_h: url=TrbActSys_types.h
          TrbActSys_data_c: url=TrbActSys_data.c
          TrbActSys_MemMap_h: url=TrbActSys_MemMap.h
          TrbActSys_nvm_c: url=TrbActSys_nvm.c
package /Components/SWC_TrbActSys/TrbActSys_IRVDatatypes
  boolean type DT_TrbActSys_LockedAftsNvm: base-type=boolean
  12 x integer type:
    DT_TrbAct_arTrbActReq_irv: base-type=uint16, lower-limit=0, upper-limit=65535
    DT_TrbAct_effCmpr_irv: base-type=uint16, lower-limit=0, upper-limit=65535
    DT_TrbAct_effTrb_irv: base-type=uint16, lower-limit=0, upper-limit=65535
    DT_TrbAct_facAdpArTrbActErr_irv: base-type=int32, lower-limit=-2147483648, upper-limit=2147483647
    DT_TrbAct_facAdpArTrbActErrFil_irv: base-type=int32, lower-limit=-2147483648, upper-limit=2147483647
    DT_TrbAct_pGradUsThrMesCorFil_irv: base-type=int16, lower-limit=-32768, upper-limit=32767
    DT_TrbAct_pGradUsThrReqFil_irv: base-type=int16, lower-limit=-32768, upper-limit=32767
    DT_TrbAct_rOpTrbActAirExtModReq_irv: base-type=uint16, lower-limit=0, upper-limit=65535
    DT_TrbActSys_ctLockRqAftsNvm: base-type=uint8, lower-limit=0, upper-limit=255
    DT_TrbActSys_IDAftsNvm: base-type=uint8, lower-limit=0, upper-limit=255
    DT_TrbActSys_stAftsNvm: base-type=uint8, lower-limit=0, upper-limit=255
    DT_TrbActSys_stRstNvmRtn: base-type=uint32, lower-limit=0, upper-limit=4294967295
